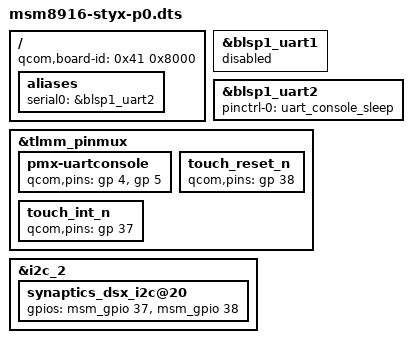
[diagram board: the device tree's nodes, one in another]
/* Copyright (c) 2014, Motorola Mobility LLC. All rights reserved.
*
* This program is free software; you can redistribute it and/or modify
* it under the terms of the GNU General Public License version 2 and
* only version 2 as published by the Free Software Foundation.
*
* This program is distributed in the hope that it will be useful,
* but WITHOUT ANY WARRANTY; without even the implied warranty of
* MERCHANTABILITY or FITNESS FOR A PARTICULAR PURPOSE.  See the
* GNU General Public License for more details.
*/

/dts-v1/;

#include "msm8916-styx.dtsi"

/ {
	qcom,board-id = <0x41 0x8000>;

	aliases {
		serial0 = &blsp1_uart2;
	};
};

&blsp1_uart1 {
	status = "disabled";
};

&blsp1_uart2 {
	status = "ok";
	pinctrl-names = "default";
	pinctrl-0 = <&uart_console_sleep>;
};

&tlmm_pinmux {
	pmx-uartconsole {
		qcom,pins = <&gp 4>, <&gp 5>;
	};

	touch_reset_n {
		qcom,pins = <&gp 38>;
	};

	touch_int_n {
		qcom,pins = <&gp 37>;
	};
};

&i2c_2 {
	synaptics_dsx_i2c@20 {
		gpios = <&msm_gpio 37 0>, /* IRQ */
			<&msm_gpio 38 0>; /* RESET - Dummy value, unused */
	};
};
